AUTOSAR XML (schema 00049)
package /ARRoot
  elements flat-map=instances=flat-instance-descriptor=SystemExtract_1.SystemExtract_1:
    system SystemExtract_1
      system mapping VehSpdCalc_SystemMaping: swc-to-impl-mapping=component=VehSpdCalcComp.SystemExtract2_SWComp, swc-to-ecu-mapping=component=VehSpdCalcComp.SystemExtract2_SWComp.SystemExtract2_SWComp
        data-mappings:
          communication-direction=IN, data-element=SystemExtract2_SWComp.VehSpdCalcComp.WhlSpdConsoldInput_RPort.UINT8
          communication-direction=OUT, data-element=SystemExtract2_SWComp.VehSpdCalcComp.VehSpdOutput_PPort.UINT8
      system mapping WhlSpdSystemMapping:
        sender-receiver-to-signal-mapping{communication-direction=IN, data-element=SystemExtract1_SWComp.WhlSpdSnsrComp.WhlSpdMeasuredInput_RPort.UINT8}
        swc-to-impl-mapping{component-implementation=WhlSpdSnsr_SWComp, component=WhlSpdSnsrComp.SystemExtract1_SWComp.SystemExtract1_SWComp}
        swc-to-ecu-mapping{component=WhlSpdSnsrComp.SystemExtract1_SWComp.SystemExtract1_SWComp, ecu-instance=WhlSpdSnsr_ECUInstance}
      system mapping WhlSpdVirtSystemMapping:
        sender-receiver-to-signal-mapping{communication-direction=OUT, data-element=SystemExtract1_SWComp.WhlSpdVirtComp.WhlSpdMeasuredOutput_PPort.UINT8}
        swc-to-impl-mapping{component-implementation=WhlSpdVirt_SWComp, component=WhlSpdVirtComp.SystemExtract1_SWComp.SystemExtract1_SWComp}
        swc-to-ecu-mapping{component=WhlSpdVirtComp.SystemExtract1_SWComp.SystemExtract1_SWComp, ecu-instance=WhlSpdVirt_ECUInstance}
      root-software-compositions:
        root sw composition prototype VehSpdCalcComp
        root sw composition prototype WhlSpdSnsrComp: flat-map=/ARRoot/
        root sw composition prototype WhlSpdVirtComp: flat-map=/ARRoot/, software-composition=TopLevelSystemExtract1
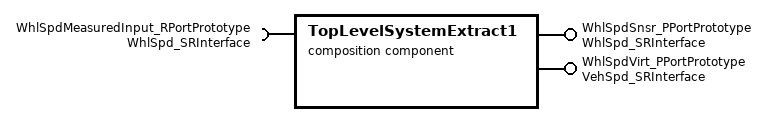
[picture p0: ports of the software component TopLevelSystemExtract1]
    composition sw component type TopLevelSystemExtract1
      require port WhlSpdMeasuredInput_RPortPrototype: required-interface=WhlSpd_SRInterface
      provide port WhlSpdSnsr_PPortPrototype: provided-interface=WhlSpd_SRInterface
      provide port WhlSpdVirt_PPortPrototype: provided-interface=VehSpd_SRInterface
      component SystemExtract1_SWComp: type=TopLevelSystemExtract1
      delegate SystemExtract1_SWComp.WhlSpdMeasuredInput_RPort <-> outer port WhlSpdMeasuredInput_RPortPrototype
      delegate SystemExtract1_SWComp.WhlSpdConsoldOutput_PPort <-> outer port WhlSpdSnsr_PPortPrototype
      delegate SystemExtract1_SWComp.WhlSpdMeasuredOutput_PPort <-> outer port WhlSpdVirt_PPortPrototype
    can cluster WhlSpdSnsr_CANCluster
      can physical channel WhlSpdSnsr_CANPhysicalChannel: comm-connectors=WhlSPdSnsr_Connector
    ecu instance WhlSpdSnsr_ECUInstance
      can communication controller WhlSpdSnsr_Controller
      can communication connector WhlSPdSnsr_Connector: comm-controller=WhlSpdSnsr_Controller
    can cluster WhlSpdVirt_CANCluster
      can physical channel WhlSpdVirt_CANPhysicalChannel: comm-connectors=WhlSpdVirt_Connector
    ecu instance WhlSpdVirt_ECUInstance
      can communication controller WhlSpdVirt_Controller
      can communication connector WhlSpdVirt_Connector: comm-controller=WhlSpdVirt_Controller
